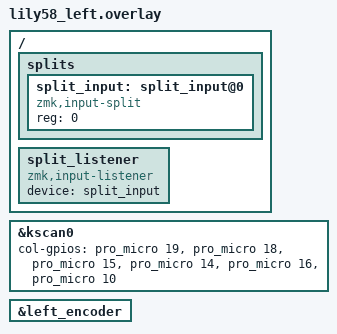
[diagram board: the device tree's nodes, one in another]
/*
 * Lily58 Pro - mitad izquierda
 * Basado en el overlay original de ZMK v0.3.
 */

#include "lily58.dtsi"

&kscan0 {
    col-gpios
        = <&pro_micro 19 GPIO_ACTIVE_HIGH>
        , <&pro_micro 18 GPIO_ACTIVE_HIGH>
        , <&pro_micro 15 GPIO_ACTIVE_HIGH>
        , <&pro_micro 14 GPIO_ACTIVE_HIGH>
        , <&pro_micro 16 GPIO_ACTIVE_HIGH>
        , <&pro_micro 10 GPIO_ACTIVE_HIGH>
        ;
};

&left_encoder {
    status = "okay";
};

/ {
    splits {
        #address-cells = <1>;
        #size-cells = <0>;

        split_input: split_input@0 {
            compatible = "zmk,input-split";
            reg = <0>;
            status = "okay";
        };
    };

    split_listener: split_listener {
        compatible = "zmk,input-listener";
        status = "okay";
        device = <&split_input>;
    };
};
